AUTOSAR XML (schema 314)
package /ComponentType
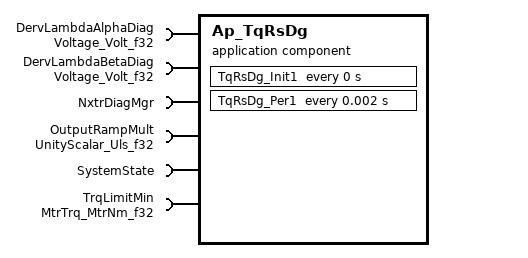
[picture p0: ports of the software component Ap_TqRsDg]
  application software component type Ap_TqRsDg
    6 x require port:
      DervLambdaAlphaDiag: unqueued-receiver-com-spec{data-element=Volt_f32, init-value=D_ZERO_ULS_F32}, required-interface=Voltage_Volt_f32
      DervLambdaBetaDiag: unqueued-receiver-com-spec{data-element=Volt_f32, init-value=D_ZERO_ULS_F32}, required-interface=Voltage_Volt_f32
      NxtrDiagMgr: required-com-specs=[GetNTCActive, GetNTCFailed, GetNTCStatus, SetNTCStatus], required-interface=NxtrDiagMgr
      OutputRampMult: unqueued-receiver-com-spec{data-element=Uls_f32, init-value=D_ZERO_ULS_F32}, required-interface=UnityScalar_Uls_f32
      SystemState: required-interface=SystemState
      TrqLimitMin: unqueued-receiver-com-spec{data-element=MtrNm_f32, init-value=D_ZERO_ULS_F32}, required-interface=MtrTrq_MtrNm_f32
  internal behavior Ap_TqRsDg_InternalBehavior: component=Ap_TqRsDg
    timing event TqRsDg_Init1_InitEvent: start-on-event=TqRsDg_Init1, period=0
    timing event TMT_TqRsDg_Per1: mode-dependency=dependent-on-mode=[SystemState.Mode.DISABLE, SystemState.Mode.OFF, SystemState.Mode.WARMINIT], start-on-event=TqRsDg_Per1, period=0.002
    port-api-options:
      enable-take-address=false, indirect-api=false, port=DervLambdaAlphaDiag
      enable-take-address=false, indirect-api=false, port=DervLambdaBetaDiag
      enable-take-address=false, indirect-api=false, port=NxtrDiagMgr
      enable-take-address=false, indirect-api=false, port=OutputRampMult
      enable-take-address=false, indirect-api=false, port=SystemState
      enable-take-address=false, indirect-api=false, port=TrqLimitMin
    runnable TqRsDg_Init1
    runnable TqRsDg_Per1
      4 x data read access:
        READ_DervLambdaAlphaDiag_Volt_f32: data-element=DervLambdaAlphaDiag.Volt_f32
        READ_DervLambdaBetaDiag_Volt_f32: data-element=DervLambdaBetaDiag.Volt_f32
        READ_OutputRampMult_Uls_f32: data-element=OutputRampMult.Uls_f32
        READ_TrqLimitMin_MtrNm_f32: data-element=TrqLimitMin.MtrNm_f32
      sync call SC_NxtrDiagMgr_SetNTCStatus: operation=NxtrDiagMgr.SetNTCStatus, timeout=0
  swc implementation Ap_TqRsDg_Implementation: behavior=Ap_TqRsDg_InternalBehavior
    code-descriptors:
      code Code: type=SRC
